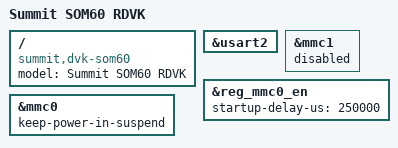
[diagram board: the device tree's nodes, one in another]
// SPDX-License-Identifier: LicenseRef-Ezurio-Clause
/*
 * at91-dvk_som60_rdvk.dts - Device Tree file for the DVK SOM60 board
 *
 * Copyright (C) 2018 Ezurio
 */

/dts-v1/;

/* SOM60 module definition */
#include "at91-som60.dtsi"

/* DVK MFG board definition */
#include "at91-dvk_su60_somc_mfg.dtsi"

/ {
	model = "Summit SOM60 RDVK";
	compatible = "summit,dvk-som60", "summit,som60", "atmel,sama5d36", "atmel,sama5d3", "atmel,sama5";
};

/* For Bluetooth */
&usart2 {
	status = "okay";
};

/* On-board 60 series radio disabled */
&mmc1 {
	status = "disabled";
};

/*
 * LWB/LWB5/LWB5+ requires minimum 150ms after power-up until first access
 * Testing shows this isn't always sufficient
 */
&reg_mmc0_en {
	startup-delay-us = <250000>;
};

&mmc0 {
	keep-power-in-suspend;
};
